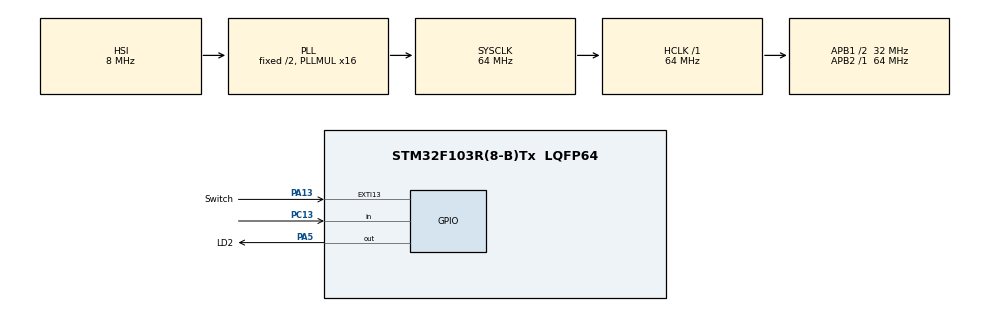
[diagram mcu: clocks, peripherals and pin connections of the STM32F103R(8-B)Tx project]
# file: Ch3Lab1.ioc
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Mcu.Family=STM32F1
Mcu.Name=STM32F103R(8-B)Tx
Mcu.Package=LQFP64
NVIC.EXTI15_10_IRQn=true\:0\:0\:false\:false\:true\:true\:true\:true
NVIC.PriorityGroup=NVIC_PRIORITYGROUP_4
PA13.GPIO_Label=Switch
PA13.GPIO_PuPd=GPIO_PULLUP
PA13.Signal=GPXTI13
PA5.GPIO_Label=LD2
PA5.GPIO_PuPd=GPIO_PULLDOWN
PA5.Signal=GPIO_Output
PC13-TAMPER-RTC.GPIO_PuPd=GPIO_NOPULL
PC13-TAMPER-RTC.Signal=GPIO_Input
ProjectManager.HeapSize=0x200
ProjectManager.StackSize=0x400
ProjectManager.TargetToolchain=STM32CubeIDE
RCC.AHBFreq_Value=64000000
RCC.APB1CLKDivider=RCC_HCLK_DIV2
RCC.APB1Freq_Value=32000000
RCC.APB1TimFreq_Value=64000000
RCC.APB2Freq_Value=64000000
RCC.APB2TimFreq_Value=64000000
RCC.HCLKFreq_Value=64000000
RCC.PLLMUL=RCC_PLL_MUL16
RCC.SYSCLKFreq_VALUE=64000000
RCC.SYSCLKSource=RCC_SYSCLKSOURCE_PLLCLK
RCC.USBFreq_Value=64000000
VP_SYS_VS_ND.Mode=No_Debug
board=custom

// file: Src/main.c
/* USER CODE BEGIN Header */
/**
 ******************************************************************************
 * @file           : main.c
 * @brief          : Main program body
 ******************************************************************************
 * @attention
 *
 * Copyright (c) 2023 STMicroelectronics.
 * All rights reserved.
 *
 * This software is licensed under terms that can be found in the LICENSE file
 * in the root directory of this software component.
 * If no LICENSE file comes with this software, it is provided AS-IS.
 *
 ******************************************************************************
 */
/* USER CODE END Header */
#include "main.h"
#include <stdbool.h>

/* USER CODE BEGIN PV */
volatile unsigned int gTick;
volatile bool bFlgPC13 = 1;
volatile bool flag = 0;
volatile bool toggle = 0;
enum {
	CURRENT_PRESSED = 0,
	CURRENT_UNPRESSED = 1
};

enum {
	FALSE = 0,
	TRUE = 1
};
void TimerISR(void)
{
  gTick = gTick + 1;
}
void clear_timer()
{
	gTick = 0;
}

bool is_current_time(int msec)
{
	if (gTick > msec)
	{
		return TRUE;
	} else {
		return FALSE;
	}
}

void delay_ms(int msec)
{
  int next_tick = gTick + msec;

  while(next_tick > gTick){
	  ;
  }
}

void HAL_GPIO_EXTI_Callback(uint16_t GPIO_Pin)
{
	if(GPIO_Pin == GPIO_PIN_13) {
		bFlgPC13 ^= 1;
		HAL_GPIO_WritePin(GPIOA, GPIO_PIN_5, bFlgPC13);
	}
}
/* USER CODE END PV */

void SystemClock_Config(void);
static void MX_GPIO_Init(void);

int main(void)
{

  /* MCU Configuration--------------------------------------------------------*/

  /* Reset of all peripherals, Initializes the Flash interface and the Systick. */
  HAL_Init();

  /* Configure the system clock */
  SystemClock_Config();

  /* Initialize all configured peripherals */
  MX_GPIO_Init();

  /* Infinite loop */
  /* USER CODE BEGIN WHILE */

  while (1) {
		//bFlgPC13 = HAL_GPIO_ReadPin(GPIOC, GPIO_PIN_13);
		//HAL_GPIO_TogglePin(GPIOA, GPIO_PIN_5);
		//if (bFlgPC13 == CURRENT_PRESSED) {

			//HAL_GPIO_TogglePin(GPIOA, GPIO_PIN_5);
		//	HAL_GPIO_WritePin(GPIOA, GPIO_PIN_5, GPIO_PIN_SET);
		//} else {
		//	HAL_GPIO_WritePin(GPIOA, GPIO_PIN_5, GPIO_PIN_RESET);
		//}
  }
    /* USER CODE END WHILE */

}

void SystemClock_Config(void)
{
  RCC_OscInitTypeDef RCC_OscInitStruct = {0};
  RCC_ClkInitTypeDef RCC_ClkInitStruct = {0};

  /** Initializes the RCC Oscillators according to the specified parameters
  * in the RCC_OscInitTypeDef structure.
  */
  RCC_OscInitStruct.OscillatorType = RCC_OSCILLATORTYPE_HSI;
  RCC_OscInitStruct.HSIState = RCC_HSI_ON;
  RCC_OscInitStruct.HSICalibrationValue = RCC_HSICALIBRATION_DEFAULT;
  RCC_OscInitStruct.PLL.PLLState = RCC_PLL_ON;
  RCC_OscInitStruct.PLL.PLLSource = RCC_PLLSOURCE_HSI_DIV2;
  RCC_OscInitStruct.PLL.PLLMUL = RCC_PLL_MUL16;
  if (HAL_RCC_OscConfig(&RCC_OscInitStruct) != HAL_OK)
  {
    Error_Handler();
  }

  /** Initializes the CPU, AHB and APB buses clocks
  */
  RCC_ClkInitStruct.ClockType = RCC_CLOCKTYPE_HCLK|RCC_CLOCKTYPE_SYSCLK
                              |RCC_CLOCKTYPE_PCLK1|RCC_CLOCKTYPE_PCLK2;
  RCC_ClkInitStruct.SYSCLKSource = RCC_SYSCLKSOURCE_PLLCLK;
  RCC_ClkInitStruct.AHBCLKDivider = RCC_SYSCLK_DIV1;
  RCC_ClkInitStruct.APB1CLKDivider = RCC_HCLK_DIV2;
  RCC_ClkInitStruct.APB2CLKDivider = RCC_HCLK_DIV1;

  if (HAL_RCC_ClockConfig(&RCC_ClkInitStruct, FLASH_LATENCY_2) != HAL_OK)
  {
    Error_Handler();
  }
}

static void MX_GPIO_Init(void)
{
  GPIO_InitTypeDef GPIO_InitStruct = {0};

  /* GPIO Ports Clock Enable */
  __HAL_RCC_GPIOC_CLK_ENABLE();
  __HAL_RCC_GPIOA_CLK_ENABLE();

  /*Configure GPIO pin Output Level */
  HAL_GPIO_WritePin(LD2_GPIO_Port, LD2_Pin, GPIO_PIN_RESET);

  /*Configure GPIO pin : PC13 */
  GPIO_InitStruct.Pin = GPIO_PIN_13;
  GPIO_InitStruct.Mode = GPIO_MODE_INPUT;
  GPIO_InitStruct.Pull = GPIO_NOPULL;
  HAL_GPIO_Init(GPIOC, &GPIO_InitStruct);

  /*Configure GPIO pin : LD2_Pin */
  GPIO_InitStruct.Pin = LD2_Pin;
  GPIO_InitStruct.Mode = GPIO_MODE_OUTPUT_PP;
  GPIO_InitStruct.Pull = GPIO_PULLDOWN;
  GPIO_InitStruct.Speed = GPIO_SPEED_FREQ_LOW;
  HAL_GPIO_Init(LD2_GPIO_Port, &GPIO_InitStruct);

  /*Configure GPIO pin : Switch_Pin */
  GPIO_InitStruct.Pin = Switch_Pin;
  GPIO_InitStruct.Mode = GPIO_MODE_IT_RISING;
  GPIO_InitStruct.Pull = GPIO_PULLUP;
  HAL_GPIO_Init(Switch_GPIO_Port, &GPIO_InitStruct);

  /* EXTI interrupt init*/
  HAL_NVIC_SetPriority(EXTI15_10_IRQn, 0, 0);
  HAL_NVIC_EnableIRQ(EXTI15_10_IRQn);

}

void Error_Handler(void)
{
	__disable_irq();
	while (1) {
	}
}
